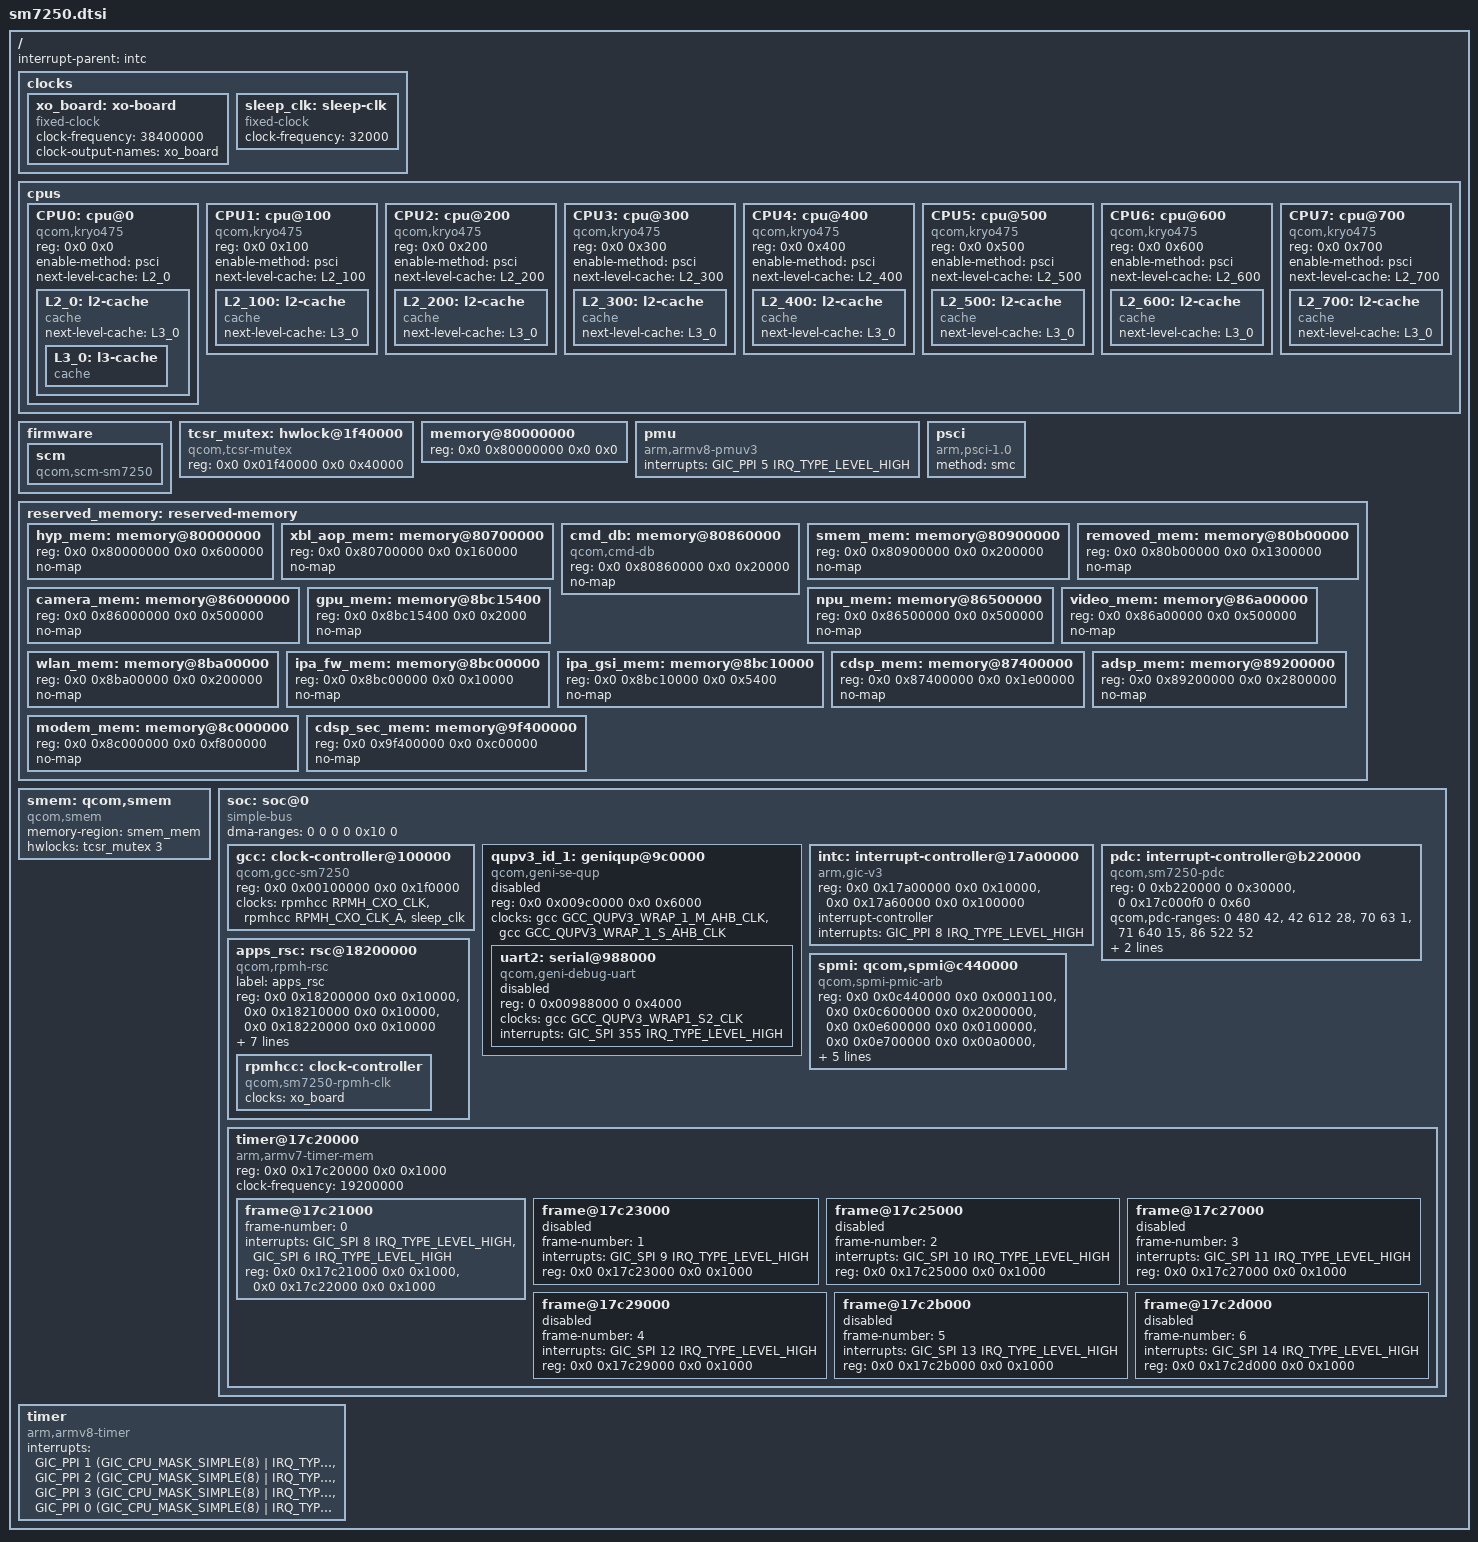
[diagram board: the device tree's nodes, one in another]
// SPDX-License-Identifier: BSD-3-Clause
/*
 * Copyright (c) 2020, The Linux Foundation. All rights reserved.
 * Copyright (c) 2026, Sreeshankar K <sreeshankar0910@gmail.com>
 */

#include <dt-bindings/clock/qcom,rpmh.h>
#include <dt-bindings/clock/qcom,gcc-sm7250.h>
#include <dt-bindings/interrupt-controller/arm-gic.h>
#include <dt-bindings/soc/qcom,rpmh-rsc.h>

/ {
	interrupt-parent = <&intc>;
	#address-cells = <2>;
	#size-cells = <2>;

	clocks {
		xo_board: xo-board {
			compatible = "fixed-clock";
			#clock-cells = <0>;
			clock-frequency = <38400000>;
			clock-output-names = "xo_board";
		};

		sleep_clk: sleep-clk {
			compatible = "fixed-clock";
			#clock-cells = <0>;
			clock-frequency = <32000>;
		};
	};
	cpus {
		#address-cells = <2>;
		#size-cells = <0>;

		CPU0: cpu@0 {
			device_type = "cpu";
			compatible = "qcom,kryo475";
			reg = <0x0 0x0>;
			enable-method = "psci";
			next-level-cache = <&L2_0>;
			L2_0: l2-cache {
				compatible = "cache";
				next-level-cache = <&L3_0>;
				L3_0: l3-cache {
					compatible = "cache";
				};
			};
		};

		CPU1: cpu@100 {
			device_type = "cpu";
			compatible = "qcom,kryo475";
			reg = <0x0 0x100>;
			enable-method = "psci";
			next-level-cache = <&L2_100>;
			L2_100: l2-cache {
				compatible = "cache";
				next-level-cache = <&L3_0>;
			};
		};

		CPU2: cpu@200 {
			device_type = "cpu";
			compatible = "qcom,kryo475";
			reg = <0x0 0x200>;
			enable-method = "psci";
			next-level-cache = <&L2_200>;
			L2_200: l2-cache {
				compatible = "cache";
				next-level-cache = <&L3_0>;
			};
		};

		CPU3: cpu@300 {
			device_type = "cpu";
			compatible = "qcom,kryo475";
			reg = <0x0 0x300>;
			enable-method = "psci";
			next-level-cache = <&L2_300>;
			L2_300: l2-cache {
				compatible = "cache";
				next-level-cache = <&L3_0>;
			};
		};

		CPU4: cpu@400 {
			device_type = "cpu";
			compatible = "qcom,kryo475";
			reg = <0x0 0x400>;
			enable-method = "psci";
			next-level-cache = <&L2_400>;
			L2_400: l2-cache {
				compatible = "cache";
				next-level-cache = <&L3_0>;
			};
		};

		CPU5: cpu@500 {
			device_type = "cpu";
			compatible = "qcom,kryo475";
			reg = <0x0 0x500>;
			enable-method = "psci";
			next-level-cache = <&L2_500>;
			L2_500: l2-cache {
				compatible = "cache";
				next-level-cache = <&L3_0>;
			};
		};

		CPU6: cpu@600 {
			device_type = "cpu";
			compatible = "qcom,kryo475";
			reg = <0x0 0x600>;
			enable-method = "psci";
			next-level-cache = <&L2_600>;
			L2_600: l2-cache {
				compatible = "cache";
				next-level-cache = <&L3_0>;
			};
		};

		CPU7: cpu@700 {
			device_type = "cpu";
			compatible = "qcom,kryo475";
			reg = <0x0 0x700>;
			enable-method = "psci";
			next-level-cache = <&L2_700>;
			L2_700: l2-cache {
				compatible = "cache";
				next-level-cache = <&L3_0>;
			};
		};
	};

	firmware {
		scm: scm {
			compatible = "qcom,scm-sm7250", "qcom,scm";
			#reset-cells = <1>;
		};
	};

	tcsr_mutex: hwlock@1f40000 {
		compatible = "qcom,tcsr-mutex";
		reg = <0x0 0x01f40000 0x0 0x40000>;
		#hwlock-cells = <1>;
	};

	memory@80000000 {
		device_type = "memory";
		/* We expect the bootloader to fill in the size */
		reg = <0x0 0x80000000 0x0 0x0>;
	};

	pmu {
		compatible = "arm,armv8-pmuv3";
		interrupts = <GIC_PPI 5 IRQ_TYPE_LEVEL_HIGH>;
	};

	psci {
		compatible = "arm,psci-1.0";
		method = "smc";
	};

	reserved_memory: reserved-memory {
		#address-cells = <2>;
		#size-cells = <2>;
		ranges;

		hyp_mem: memory@80000000 {
			reg = <0x0 0x80000000 0x0 0x600000>;
			no-map;
		};

		xbl_aop_mem: memory@80700000 {
			reg = <0x0 0x80700000 0x0 0x160000>;
			no-map;
		};

		cmd_db: memory@80860000 {
			compatible = "qcom,cmd-db";
			reg = <0x0 0x80860000 0x0 0x20000>;
			no-map;
		};

		smem_mem: memory@80900000 {
			reg = <0x0 0x80900000 0x0 0x200000>;
			no-map;
		};

		removed_mem: memory@80b00000 {
			reg = <0x0 0x80b00000 0x0 0x1300000>;
			no-map;
		};

		camera_mem: memory@86000000 {
			reg = <0x0 0x86000000 0x0 0x500000>;
			no-map;
		};

		gpu_mem: memory@8bc15400 {
			reg = <0x0 0x8bc15400 0x0 0x2000>;
			no-map;
		};

		npu_mem: memory@86500000 {
			reg = <0x0 0x86500000 0x0 0x500000>;
			no-map;
		};

		video_mem: memory@86a00000 {
			reg = <0x0 0x86a00000 0x0 0x500000>;
			no-map;
		};

		wlan_mem: memory@8ba00000 {
			reg = <0x0 0x8ba00000 0x0 0x200000>;
			no-map;
		};

		ipa_fw_mem: memory@8bc00000 {
			reg = <0x0 0x8bc00000 0x0 0x10000>;
			no-map;
		};

		ipa_gsi_mem: memory@8bc10000 {
			reg = <0x0 0x8bc10000 0x0 0x5400>;
			no-map;
		};

		cdsp_mem: memory@87400000 {
			reg = <0x0 0x87400000 0x0 0x1e00000>;
			no-map;
		};

		adsp_mem: memory@89200000 {
			reg = <0x0 0x89200000 0x0 0x2800000>;
			no-map;
		};

		modem_mem: memory@8c000000 {
			reg = <0x0 0x8c000000 0x0 0xf800000>;
			no-map;
		};

		cdsp_sec_mem: memory@9f400000 {
			reg = <0x0 0x9f400000 0x0 0xc00000>;
			no-map;
		};
	};

	smem: qcom,smem {
		compatible = "qcom,smem";
		memory-region = <&smem_mem>;
		hwlocks = <&tcsr_mutex 3>;
	};

	soc: soc@0 {
		#address-cells = <2>;
		#size-cells = <2>;
		ranges = <0 0 0 0 0x10 0>;
		dma-ranges = <0 0 0 0 0x10 0>;
		compatible = "simple-bus";

		gcc: clock-controller@100000 {
			compatible = "qcom,gcc-sm7250";
			reg = <0x0 0x00100000 0x0 0x1f0000>;
			#clock-cells = <1>;
			#reset-cells = <1>;
			#power-domain-cells = <1>;
			clock-names = "bi_tcxo",
				      "bi_tcxo_ao",
				      "sleep_clk";
			clocks = <&rpmhcc RPMH_CXO_CLK>,
				 <&rpmhcc RPMH_CXO_CLK_A>,
				 <&sleep_clk>;
		};

		qupv3_id_1: geniqup@9c0000 {
			compatible = "qcom,geni-se-qup";
			reg = <0x0 0x009c0000 0x0 0x6000>;
			clock-names = "m-ahb", "s-ahb";
			clocks = <&gcc GCC_QUPV3_WRAP_1_M_AHB_CLK>,
				 <&gcc GCC_QUPV3_WRAP_1_S_AHB_CLK>;
			#address-cells = <2>;
			#size-cells = <2>;
			ranges;
			status = "disabled";

			uart2: serial@988000 {
			compatible = "qcom,geni-debug-uart";
				reg = <0 0x00988000 0 0x4000>;
				clock-names = "se";
				clocks = <&gcc GCC_QUPV3_WRAP1_S2_CLK>;
				interrupts = <GIC_SPI 355 IRQ_TYPE_LEVEL_HIGH>;
				status = "disabled";
			};
		};

		intc: interrupt-controller@17a00000 {
			compatible = "arm,gic-v3";
			reg = <0x0 0x17a00000 0x0 0x10000>,     /* GICD */
			      <0x0 0x17a60000 0x0 0x100000>;    /* GICR * 8 */
			#interrupt-cells = <3>;
			interrupt-controller;
			interrupts = <GIC_PPI 8 IRQ_TYPE_LEVEL_HIGH>;
		};

		pdc: interrupt-controller@b220000 {
			compatible = "qcom,sm7250-pdc", "qcom,pdc";
			reg = <0 0xb220000 0 0x30000>, <0 0x17c000f0 0 0x60>;
			qcom,pdc-ranges = <0 480 42>, <42 612 28>,
					  <70 63 1>, <71 640 15>, <86 522 52>;
			#interrupt-cells = <2>;
			interrupt-parent = <&intc>;
			interrupt-controller;
		};

		spmi: qcom,spmi@c440000 {
			compatible = "qcom,spmi-pmic-arb";
			reg = <0x0 0x0c440000 0x0 0x0001100>,
			      <0x0 0x0c600000 0x0 0x2000000>,
			      <0x0 0x0e600000 0x0 0x0100000>,
			      <0x0 0x0e700000 0x0 0x00a0000>,
			      <0x0 0x0c40a000 0x0 0x0026000>;
			reg-names = "core", "chnls", "obsrvr", "intr", "cnfg";
			interrupt-names = "periph_irq";
			interrupts-extended = <&pdc 1 IRQ_TYPE_LEVEL_HIGH>;
			qcom,ee = <0>;
			qcom,channel = <0>;
			#address-cells = <1>;
			#size-cells = <1>;
			interrupt-controller;
			#interrupt-cells = <4>;
		};

		apps_rsc: rsc@18200000 {
			label = "apps_rsc";
			compatible = "qcom,rpmh-rsc";
			reg = <0x0 0x18200000 0x0 0x10000>,
			      <0x0 0x18210000 0x0 0x10000>,
			      <0x0 0x18220000 0x0 0x10000>;
			reg-names = "drv-0", "drv-1", "drv-2";
			interrupts = <GIC_SPI 3 IRQ_TYPE_LEVEL_HIGH>,
				     <GIC_SPI 4 IRQ_TYPE_LEVEL_HIGH>,
				     <GIC_SPI 5 IRQ_TYPE_LEVEL_HIGH>;
			qcom,tcs-offset = <0xd00>;
			qcom,drv-id = <2>;
			qcom,tcs-config = <ACTIVE_TCS  2>, <SLEEP_TCS   3>,
					  <WAKE_TCS    3>, <CONTROL_TCS 1>;

			rpmhcc: clock-controller {
				compatible = "qcom,sm7250-rpmh-clk";
				#clock-cells = <1>;
				clock-names = "xo";
				clocks = <&xo_board>;
			};
		};

		timer@17c20000 {
			#address-cells = <1>;
			#size-cells = <1>;
			ranges;
			compatible = "arm,armv7-timer-mem";
			reg = <0x0 0x17c20000 0x0 0x1000>;
			clock-frequency = <19200000>;

			frame@17c21000 {
				frame-number = <0>;
				interrupts = <GIC_SPI 8 IRQ_TYPE_LEVEL_HIGH>,
					     <GIC_SPI 6 IRQ_TYPE_LEVEL_HIGH>;
				reg = <0x0 0x17c21000 0x0 0x1000>,
				      <0x0 0x17c22000 0x0 0x1000>;
			};

			frame@17c23000 {
				frame-number = <1>;
				interrupts = <GIC_SPI 9 IRQ_TYPE_LEVEL_HIGH>;
				reg = <0x0 0x17c23000 0x0 0x1000>;
				status = "disabled";
			};

			frame@17c25000 {
				frame-number = <2>;
				interrupts = <GIC_SPI 10 IRQ_TYPE_LEVEL_HIGH>;
				reg = <0x0 0x17c25000 0x0 0x1000>;
				status = "disabled";
			};

			frame@17c27000 {
				frame-number = <3>;
				interrupts = <GIC_SPI 11 IRQ_TYPE_LEVEL_HIGH>;
				reg = <0x0 0x17c27000 0x0 0x1000>;
				status = "disabled";
			};

			frame@17c29000 {
				frame-number = <4>;
				interrupts = <GIC_SPI 12 IRQ_TYPE_LEVEL_HIGH>;
				reg = <0x0 0x17c29000 0x0 0x1000>;
				status = "disabled";
			};

			frame@17c2b000 {
				frame-number = <5>;
				interrupts = <GIC_SPI 13 IRQ_TYPE_LEVEL_HIGH>;
				reg = <0x0 0x17c2b000 0x0 0x1000>;
				status = "disabled";
			};

			frame@17c2d000 {
				frame-number = <6>;
				interrupts = <GIC_SPI 14 IRQ_TYPE_LEVEL_HIGH>;
				reg = <0x0 0x17c2d000 0x0 0x1000>;
				status = "disabled";
			};
		};

	};

	timer {
		compatible = "arm,armv8-timer";
		interrupts = <GIC_PPI 1
				(GIC_CPU_MASK_SIMPLE(8) | IRQ_TYPE_LEVEL_LOW)>,
			     <GIC_PPI 2
				(GIC_CPU_MASK_SIMPLE(8) | IRQ_TYPE_LEVEL_LOW)>,
			     <GIC_PPI 3
				(GIC_CPU_MASK_SIMPLE(8) | IRQ_TYPE_LEVEL_LOW)>,
			     <GIC_PPI 0
				(GIC_CPU_MASK_SIMPLE(8) | IRQ_TYPE_LEVEL_LOW)>;
	};
};
